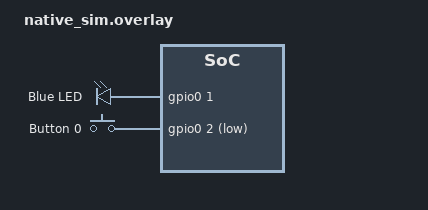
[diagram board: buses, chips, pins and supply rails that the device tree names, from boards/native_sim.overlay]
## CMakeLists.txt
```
# Copyright (c) 2026 Lingao Meng
# SPDX-License-Identifier: Apache-2.0
#
# zbot - An open-source embedded AI Agent for Zephyr RTOS
# Supported boards: nRF7002-DK (nRF5340 + nRF7002 WiFi), native_sim

cmake_minimum_required(VERSION 3.20.0)

find_package(Zephyr REQUIRED HINTS $ENV{ZEPHYR_BASE})

project(zbot VERSION 0.1.0)

target_sources(app PRIVATE
    src/main.c
    src/tools.c
    src/memory.c
    src/config.c
    src/llm_client.c
    src/agent.c
    src/shell_cmd.c
    src/telegram.c
    src/json_util.c
    src/skills/skill.c
)

target_include_directories(app PRIVATE src src/skills src/tools)

set(gen_dir ${ZEPHYR_BINARY_DIR}/include/generated/)

# OpenRouter TLS certificate
generate_inc_file_for_target(
    app
    src/certs/openrouter/cert-3.der
    ${gen_dir}/openrouter/https-cert.der.inc
)

configure_file(
    ${CMAKE_CURRENT_SOURCE_DIR}/src/AGENTS.md.in
    ${gen_dir}/AGENTS.md
    @ONLY
)

# Agent system prompt
generate_inc_file_for_target(
    app
    ${gen_dir}/AGENTS.md
    ${gen_dir}/AGENTS.md.inc
)

add_subdirectory(src/tools)
add_subdirectory(src/skills)
```

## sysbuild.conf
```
#
# Copyright (c) 2024 Nordic Semiconductor ASA
#
# SPDX-License-Identifier: LicenseRef-Nordic-5-Clause
#
# nRF7002 WiFi companion image — only needed for nRF7002DK.
# For other boards (e.g. native_sim) this file is a no-op because
# SB_CONFIG_WIFI_NRF70 is not selected by those board configs.
```

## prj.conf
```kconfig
# =============================================================================
# zbot - Zephyr AI Agent Configuration (all boards)
# =============================================================================

# --- Kernel / Stack ---
CONFIG_MAIN_STACK_SIZE=2048
CONFIG_SYSTEM_WORKQUEUE_STACK_SIZE=16384

CONFIG_PRINTK=y

# --- Shell (for runtime key configuration) ---
CONFIG_SHELL=y
CONFIG_SHELL_BACKEND_SERIAL=y
CONFIG_SHELL_STACK_SIZE=8172
CONFIG_SHELL_CMD_BUFF_SIZE=512
CONFIG_SHELL_HISTORY=y
CONFIG_SHELL_HISTORY_BUFFER=512
CONFIG_SHELL_LOG_BACKEND=n

# --- Networking ---
CONFIG_NETWORKING=y
CONFIG_NET_IPV4=y
CONFIG_NET_TCP=y
CONFIG_NET_SOCKETS=y
CONFIG_NET_SOCKETS_TLS_MAX_CONTEXTS=4
CONFIG_NET_SOCKETS_TLS_MAX_CREDENTIALS=4
CONFIG_NET_SOCKETS_TLS_MAX_CIPHERSUITES=2
CONFIG_DNS_RESOLVER=y

# --- Network buffers ---
CONFIG_NET_PKT_RX_COUNT=8
CONFIG_NET_PKT_TX_COUNT=8
CONFIG_NET_BUF_RX_COUNT=64
CONFIG_NET_BUF_TX_COUNT=64
# NET_BUF_DATA_SIZE depends on NET_BUF_FIXED_DATA_SIZE; enable the guard first.
CONFIG_NET_BUF_FIXED_DATA_SIZE=y
CONFIG_NET_BUF_DATA_SIZE=256

# --- HTTP Client ---
CONFIG_HTTP_CLIENT=y

# --- TLS / mbedTLS ---
CONFIG_MBEDTLS=y
CONFIG_MBEDTLS_BUILTIN=y
CONFIG_NET_SOCKETS_SOCKOPT_TLS=y
CONFIG_TLS_CREDENTIALS=y
# MBEDTLS_HEAP_SIZE lives inside "if MBEDTLS_ENABLE_HEAP"
CONFIG_MBEDTLS_ENABLE_HEAP=y
CONFIG_MBEDTLS_HEAP_SIZE=65536
CONFIG_MBEDTLS_SSL_MAX_CONTENT_LEN=8192
CONFIG_MBEDTLS_SSL_SERVER_NAME_INDICATION=y
CONFIG_MBEDTLS_CIPHERSUITE_TLS_ECDHE_ECDSA_WITH_AES_128_GCM_SHA256=y
# TLS 1.2 ciphersuite — required to pull in the SSL module (mbedtls_ssl_*).
# Without at least one ciphersuite, MBEDTLS_SSL_PROTO_TLS1_2 is never selected
# and all mbedtls_ssl_init/setup/handshake/... symbols are absent at link time.
CONFIG_MBEDTLS_CIPHERSUITE_TLS_ECDHE_RSA_WITH_AES_128_CBC_SHA256=y

CONFIG_SETTINGS=y
CONFIG_SETTINGS_RUNTIME=y
CONFIG_SETTINGS_NVS=y

CONFIG_NVS=y
CONFIG_FLASH=y
CONFIG_FLASH_MAP=y

# --- Logging ---
CONFIG_LOG=y
CONFIG_LOG_DEFAULT_LEVEL=3
CONFIG_LOG_BUFFER_SIZE=4096
CONFIG_LOG_BACKEND_UART=y
CONFIG_PRINTK=y

# --- Reboot support ---
CONFIG_REBOOT=y
```

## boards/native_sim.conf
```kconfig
# =============================================================================
# zbot - Board-specific config for native_sim (Linux host simulation)
# =============================================================================

# --- Native networking (offloaded sockets via host stack) ---
# Use the native Linux network stack via offloaded socket API.
CONFIG_NET_DRIVERS=y
CONFIG_NET_SOCKETS_OFFLOAD=y
CONFIG_NET_NATIVE_OFFLOADED_SOCKETS=y
CONFIG_NET_DHCPV4=y

CONFIG_TEST_RANDOM_GENERATOR=y

# --- POSIX / libc ---
# native_sim provides a full libc; enable POSIX API for compatibility.
CONFIG_REQUIRES_FULL_LIBC=y
CONFIG_POSIX_API=y

# Optional but recommended for native_sim + nsos
CONFIG_ETH_NATIVE_TAP=n
CONFIG_NET_IPV6_DAD=n

CONFIG_MBEDTLS_HASH_ALL_ENABLED=y

# --- GPIO emulation ---
# gpio_emul driver is auto-selected by the DTS compatible "zephyr,gpio-emul".
# Explicitly enable it here as a safety net.
CONFIG_GPIO=y
CONFIG_GPIO_EMUL=y

# Debug
CONFIG_NET_LOG=y
```

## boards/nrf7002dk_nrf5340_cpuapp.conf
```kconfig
# =============================================================================
# zbot - Board-specific config for nRF7002-DK (nRF5340 + nRF7002 WiFi)
# =============================================================================

# --- WiFi (nRF7002) ---
# WIFI_NRF7002 is auto-selected by DT (DT_HAS_NORDIC_NRF7002_QSPI_ENABLED).
# WIFI_NM_WPA_SUPPLICANT is auto-selected by the nrf_wifi driver.
# Do NOT set WIFI_NRF700X or WPA_SUPP — those symbols no longer exist.
CONFIG_WIFI=y
CONFIG_NET_L2_WIFI_MGMT=y
CONFIG_NET_DHCPV4=y
# WiFi connection is handled by 'zbot wifi' commands (shell_cmd.c).
# The built-in wifi shell is intentionally disabled to keep the command
# surface under the single 'zbot' root.

# --- WiFi Credentials (Zephyr built-in, uses SETTINGS+NVS backend) ---
# wifi_credentials stores SSID/pass; NET_REQUEST_WIFI_CONNECT_STORED iterates them.
CONFIG_WIFI_CREDENTIALS=y
CONFIG_WIFI_CREDENTIALS_BACKEND_SETTINGS=y
CONFIG_WIFI_CREDENTIALS_CONNECT_STORED=y
CONFIG_WIFI_CREDENTIALS_SHELL=n

# --- Entropy / RNG ---
# nRF5340 app core has no RNG peripheral in its DTS. The psa-crypto-rng driver
# crashes at PRE_KERNEL_1 (heap not ready). Instead:
#   - TEST_RANDOM_GENERATOR: allows a non-CSPRNG source to satisfy sys_rand_get
#   - TIMER_RANDOM_GENERATOR: provides z_impl_sys_rand_get via system timer
#     (sufficient for TCP ISN and DHCP; not used for TLS key material)
# TLS/mbedTLS crypto RNG is provided by MBEDTLS_PSA_CRYPTO_EXTERNAL_RNG
# which is already set in the board defconfig and uses the software PSA backend.
CONFIG_ENTROPY_GENERATOR=y
CONFIG_TEST_RANDOM_GENERATOR=y
CONFIG_TIMER_RANDOM_GENERATOR=y
```

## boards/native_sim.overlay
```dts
/*
 * Copyright (c) 2026 Lingao Meng
 *
 * SPDX-License-Identifier: Apache-2.0
 *
 * zbot - native_sim GPIO overlay
 *
 * The native_sim base DTS already provides:
 *   gpio0 (zephyr,gpio-emul) — pin 0 → led0
 *
 * This overlay extends gpio0 to 3 pins and adds led1 + sw0 (button0)
 * so that gpio_read / gpio_write tools work the same as on nRF7002-DK.
 */

#include <zephyr/dt-bindings/gpio/gpio.h>

/* Extend the emulated GPIO controller to cover the pins we need */
&gpio0 {
	ngpios = <3>;
};

/ {
	leds {
		compatible = "gpio-leds";

		led1: led_1 {
			gpios = <&gpio0 1 GPIO_ACTIVE_HIGH>;
			label = "Blue LED";
		};
	};

	buttons {
		compatible = "gpio-keys";

		button0: button_0 {
			gpios = <&gpio0 2 (GPIO_PULL_UP | GPIO_ACTIVE_LOW)>;
			label = "Button 0";
		};
	};

	aliases {
		led1 = &led1;
		sw0  = &button0;
	};
};
```

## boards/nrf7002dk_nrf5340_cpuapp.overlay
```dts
/*
 * SPDX-License-Identifier: Apache-2.0
 * nRF7002-DK device tree overlay for ZephyrClaw
 *
 * Ensures storage_partition exists for NVS.
 * The nRF7002-DK (nRF5340) internal flash layout already includes a
 * storage partition in the upstream DTS; this overlay confirms it.
 */

/ {
    chosen {
        zephyr,console = &uart0;
        zephyr,shell-uart = &uart0;
        /*
         * Do NOT add zephyr,entropy here.
         * nRF5340 app core has no RNG peripheral in DTS.
         * The psa-crypto-rng driver calls psa_crypto_init() at PRE_KERNEL_1
         * before the heap is ready, causing a hard fault with no output.
         * Instead, use TEST_RANDOM_GENERATOR + TIMER_RANDOM_GENERATOR in prj.conf
         * to satisfy sys_rand_get(). TLS crypto RNG is handled separately by
         * MBEDTLS_PSA_CRYPTO_EXTERNAL_RNG (set in board defconfig).
         */
    };
};

/*
 * Ensure NVS storage partition is available.
 * On nRF5340 the storage partition is typically defined in:
 *   boards/nordic/nrf7002dk/nrf5340_cpuapp_common.dtsi
 * If it is missing on your SDK version, uncomment and adjust below:
 */

/*
&flash0 {
    partitions {
        compatible = "fixed-partitions";
        #address-cells = <1>;
        #size-cells = <1>;

        boot_partition: partition@0 {
            label = "mcuboot";
            reg = <0x00000000 0x00010000>;
        };

        slot0_partition: partition@10000 {
            label = "image-0";
            reg = <0x00010000 0x00070000>;
        };

        slot1_partition: partition@80000 {
            label = "image-1";
            reg = <0x00080000 0x00070000>;
        };

        storage_partition: partition@f0000 {
            label = "storage";
            reg = <0x000f0000 0x00008000>;
        };
    };
};
*/
```

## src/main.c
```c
/*
 * Copyright (c) 2026 Lingao Meng
 *
 * SPDX-License-Identifier: Apache-2.0
 *
 * zbot - Main Entry Point
 *
 * WiFi (boards with CONFIG_WIFI, e.g. nRF7002-DK):
 *   Use 'zbot wifi connect <ssid> [pass]' to connect and save credentials.
 *   On next boot, config_init() auto-connects using the saved credentials.
 *
 * Without WiFi (e.g. native_sim):
 *   The network stack is provided by the host OS; no WiFi management needed.
 *
 * API key:
 *   'zbot key <key>'  — set and persist to flash
 */

#include <zephyr/kernel.h>
#include <zephyr/logging/log.h>
#include <zephyr/net/net_if.h>
#if defined(CONFIG_WIFI)
#include <zephyr/net/net_event.h>
#include <zephyr/net/wifi_mgmt.h>
#endif

#include "config.h"
#include "memory.h"
#include "llm_client.h"
#include "agent.h"
#include "tools.h"
#include "telegram.h"

LOG_MODULE_REGISTER(zbot_main, LOG_LEVEL_INF);

#if defined(CONFIG_WIFI)
#define WIFI_MGMT_EVENTS (NET_EVENT_WIFI_CONNECT_RESULT | NET_EVENT_WIFI_DISCONNECT_RESULT)

static struct net_mgmt_event_callback g_wifi_cb;
static K_SEM_DEFINE(g_wifi_connected_sem, 0, 1);
static volatile bool g_wifi_connected;

static void wifi_event_handler(struct net_mgmt_event_callback *cb, uint64_t mgmt_event,
			       struct net_if *iface)
{
	if (mgmt_event == NET_EVENT_WIFI_CONNECT_RESULT) {
		const struct wifi_status *status = (const struct wifi_status *)cb->info;

		if (status->status == 0) {
			LOG_INF("WiFi connected!");
			g_wifi_connected = true;
			k_sem_give(&g_wifi_connected_sem);
		} else {
			LOG_WRN("WiFi connect failed (status %d)", status->status);
		}
	} else if (mgmt_event == NET_EVENT_WIFI_DISCONNECT_RESULT) {
		LOG_WRN("WiFi disconnected");
		g_wifi_connected = false;
	}
}
#endif /* CONFIG_WIFI */

static void print_banner(void)
{
	printk("\n");
	printk("╔══════════════════════════════════════════════╗\n");
	printk("║        zbot - Embedded AI Agent              ║\n");
	printk("║   Board: %-36s║\n", CONFIG_BOARD "  |  Zephyr RTOS");
	printk("║   Version: 0.1.0     |  License: Apache-2.0  ║\n");
	printk("╚══════════════════════════════════════════════╝\n");
	printk("\n");
	printk("Quick start:\n");
#if defined(CONFIG_WIFI)
	printk("  1. Connect to WiFi (saves credentials for auto-connect):\n");
	printk("       zbot wifi connect <SSID> <password>\n");
	printk("  2. Set API key (saved to flash):\n");
	printk("       zbot key sk-...\n");
#else
	printk("  1. Set API key (saved to flash):\n");
	printk("       zbot key sk-...\n");
#endif
	printk("  2. [Optional] Change model/endpoint:\n");
	printk("       zbot model gpt-4o-mini\n");
	printk("       zbot host openrouter.ai\n");
	printk("  3. Chat:\n");
	printk("       Hello! What can you do?\n");
	printk("  4. Telegram bot (optional):\n");
	printk("       zbot telegram token <BOT_TOKEN>\n");
	printk("       zbot telegram start\n");
	printk("  5. Other commands:\n");
	printk("       zbot status              -- show config\n");
#if defined(CONFIG_WIFI)
	printk("       zbot wifi status         -- show saved WiFi SSID\n");
#endif
	printk("       zbot history             -- show conversation\n");
	printk("       zbot summary             -- show NVS summary\n");
	printk("       zbot skill list\n");
	printk("       zbot tools\n");
	printk("\n");
}

int main(void)
{
	const char *summary;
	int rc;

	printk("Start\n");

	/* Memory — NVS mount and load persisted summary */
	rc = memory_init();
	if (rc < 0) {
		LOG_WRN("Memory/NVS init warning: %d (continuing without persistence)", rc);
	}

#if defined(CONFIG_WIFI)
	/* Register WiFi event callback */
	net_mgmt_init_event_callback(&g_wifi_cb, wifi_event_handler, WIFI_MGMT_EVENTS);
	net_mgmt_add_event_callback(&g_wifi_cb);
#endif

	/* Config — load API key + (if WiFi board) credentials from NVS; auto-connect */
	config_init();

	/* LLM client — register TLS CA certificate once at boot */
	llm_client_init();

	/* Agent */
	rc = agent_init();
	if (rc < 0) {
		LOG_ERR("Agent init failed: %d", rc);
		return rc;
	}

	/* Telegram */
	if (config_has_tg_token()) {
		rc = telegram_start();
		if (rc < 0) {
			LOG_WRN("Telegram auto-start failed: %d", rc);
		}
	}

	/* Print banner */
	print_banner();

	/* Log persisted summary if available */
	summary = memory_get_summary();
	if (summary != NULL) {
		LOG_DBG("Loaded prior context from NVS: %.80s...", summary);
		printk("  [Prior session context loaded from NVS]\n\n");
	}

	/* Idle — shell handles everything else */
	while (1) {
		k_sleep(K_SECONDS(30));

#if defined(CONFIG_WIFI)
		if (g_wifi_connected) {
			LOG_DBG("Heartbeat — WiFi up");
		}
#endif
	}

	return 0;
}
```

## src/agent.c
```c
/*
 * Copyright (c) 2026 Lingao Meng
 *
 * SPDX-License-Identifier: Apache-2.0
 *
 * zbot - Agent Module Implementation
 *
 * Implements the ReAct (Reason + Act) loop for tool-augmented LLM interaction.
 */

#include <zephyr/kernel.h>
#include <zephyr/logging/log.h>
#include <string.h>
#include <stdio.h>
#include <errno.h>

#include "agent.h"
#include "memory.h"
#include "tools.h"
#include "config.h"
#include "llm_client.h"
#include "json_util.h"

LOG_MODULE_REGISTER(zbot_agent, LOG_LEVEL_INF);

/* System prompt embedded from src/AGENT.md at build time */
const char agent_system_prompt[] = {
#include "AGENTS.md.inc"
	0x00
};

struct tool_turn_ctx {
	size_t pos;

	int call_count;

	const char *content;

	struct {
		const struct llm_tool_call *call;
		char results[LLM_MAX_TOOL_CALLS][TOOLS_RESULT_MAX_LEN];
	} react;
};

struct summary_ctx {
	const char *roles[MEMORY_COMPRESS_COUNT];
	const char *contents[MEMORY_COMPRESS_COUNT];
	const char *prior;
	int count;
};

static int summary_messages_cb(char *buf, size_t buf_len, void *args)
{
	const struct llm_config *cfg = config_get();
	struct summary_ctx *ctx = args;
	const char *prefix;
	size_t pos = 0;
	int n;

	n = snprintf(buf + pos, buf_len - pos,
		     "{\"model\":\"%s\","
		     "\"max_completion_tokens\":%d,"
		     "\"messages\":",
		     cfg->model, cfg->max_tokens);
	if (n < 0 || (size_t)n >= buf_len - pos) {
		return -ENOMEM;
	}

	pos += (size_t)n;


	n = snprintf(buf + pos, buf_len - pos, "[{\"role\":\"system\",\"content\":\"");
	if (n < 0 || (size_t)n >= buf_len - pos) {
		return -ENOMEM;
	}

	pos += n;

	/* 1. System message — escape directly into buf */
	n = json_escape(agent_system_prompt, buf + pos, buf_len - pos);
	if ((size_t)n >= buf_len - pos) {
		return -ENOMEM;
	}

	pos += n;

	n = snprintf(buf + pos, buf_len - pos, "\"},");
	if (n < 0 || (size_t)n >= buf_len - pos) {
		return -ENOMEM;
	}

	pos += n;

	if (ctx->prior != NULL) {
		n = snprintf(buf + pos, buf_len - pos,
			     "{\"role\":\"user\",\"content\":\"[Prior summary] ");
		if (n < 0 || (size_t)n >= buf_len - pos) {
			return -ENOMEM;
		}
		pos += (size_t)n;

		n = json_escape(ctx->prior, buf + pos, buf_len - pos);
		if ((size_t)n >= buf_len - pos) {
			return -ENOMEM;
		}
		pos += (size_t)n;

		n = snprintf(buf + pos, buf_len - pos,
			     "\"},"
			     "{\"role\":\"assistant\",\"content\":\"Understood.\"},");
		if (n < 0 || (size_t)n >= buf_len - pos) {
			return -ENOMEM;
		}
		pos += (size_t)n;
	}

	prefix = (ctx->prior != NULL) ?
		  "Update the prior summary to include the following new turns." :
		  "Summarise the following conversation.";

	n = snprintf(buf + pos, buf_len - pos, "{\"role\":\"user\",\"content\":\"%s %s",
		     prefix, "For future context. Be factual and concise.");
	if (n < 0 || pos + (size_t)n >= buf_len) {
		return -ENOMEM;
	}

	pos += (size_t)n;

	n = snprintf(buf + pos, buf_len - pos, "Keep the result not exceed %d bytes.\\n",
		     MEMORY_SUMMARY_MAX_LEN);
	if (n < 0 || pos + (size_t)n >= buf_len) {
		return -ENOMEM;
	}

	pos += (size_t)n;

	for (int i = 0; i < ctx->count; i++) {
		n = snprintf(buf + pos, buf_len - pos, "%s: ", ctx->roles[i]);
		if (n < 0 || (size_t)n >= buf_len - pos) {
			return -ENOMEM;
		}
		pos += (size_t)n;

		n = json_escape(ctx->contents[i], buf + pos, buf_len - pos);
		if ((size_t)n >= buf_len - pos) {
			return -ENOMEM;
		}
		pos += (size_t)n;

		n = snprintf(buf + pos, buf_len - pos, "\\n");
		if (n < 0 || (size_t)n >= buf_len - pos) {
			return -ENOMEM;
		}
		pos += (size_t)n;
	}

	n = snprintf(buf + pos, buf_len - pos, "\"}]");
	if (n < 0 || pos + (size_t)n >= buf_len) {
		return -ENOMEM;
	}

	pos += (size_t)n;

	return (int)pos;
}

int agent_request_summary(agent_format_fn_t format_fn, char *out_buf, size_t out_len)
{
	struct summary_ctx ctx;
	struct llm_response resp;
	int count, rc;

	if (!format_fn || !out_buf || out_len == 0) {
		return -EINVAL;
	}

	count = format_fn(ctx.roles, ctx.contents, MEMORY_COMPRESS_COUNT);
	if (count < 0) {
		return count;
	}

	if (count == 0) {
		return -ENODATA;
	}

	ctx.count = count;
	ctx.prior = memory_get_summary();

	rc = llm_chat(summary_messages_cb, NULL, &resp, &ctx);
	if (rc == 0 && resp.content[0] != '\0') {
		strncpy(out_buf, resp.content, out_len - 1);
		out_buf[out_len - 1] = '\0';
		LOG_INF("agent_request_summary: %zu chars", strlen(out_buf));
		return 0;
	}

	LOG_WRN("agent_request_summary failed: %d", rc);

	return rc != 0 ? rc : -ENODATA;
}

static int messages_cb(char *buf, size_t buf_len, void *args)
{
	struct tool_turn_ctx *tc = args;
	bool first = false;
	size_t pos;
	int n;

	/*
	 * First tool-call iteration: build the base history and cache the
	 * position so subsequent iterations can skip the rebuild.
	 */
	if (tc->pos == 0) {
		n = memory_build_messages_json(buf, buf_len);
		if (n < 0) {
			return n;
		}

		first = true;
		tc->pos = (size_t)n;
	}

	/*
	 * Strip the closing ']' written by memory_build_messages_json so we
	 * can append more elements, then re-add it at the end.
	 */
	pos = tc->pos;
	if (pos == 0 || buf[pos - 1] != ']') {
		return -EINVAL;
	}
	pos--; /* overwrite the trailing ']' */

	n = snprintf(buf + pos, buf_len - pos, ",{\"role\":\"%s\",\"content\":\"",
		     first ? "user" : "assistant");
	if (n < 0 || (size_t)n >= buf_len - pos) {
		return -ENOMEM;
	}
	pos += (size_t)n;

	if (tc->content) {
		n = json_escape(tc->content, buf + pos, buf_len - pos);
		if ((size_t)n >= buf_len - pos) {
			return -ENOMEM;
		}
		pos += (size_t)n;
	}

	if (first) {
		n = snprintf(buf + pos, buf_len - pos, "\"}]");
		if (n < 0 || (size_t)n >= buf_len - pos) {
			return -ENOMEM;
		}

		pos += (size_t)n;
		tc->pos = pos;

		return (int)pos;
	}

	n = snprintf(buf + pos, buf_len - pos, "\",\"tool_calls\":[");
	if (n < 0 || (size_t)n >= buf_len - pos) {
		return -ENOMEM;
	}
	pos += (size_t)n;

	for (int i = 0; i < tc->call_count; i++) {
		const struct llm_tool_call *call = &tc->react.call[i];

		n = snprintf(buf + pos, buf_len - pos,
			     "%s{\"id\":\"%s\","
			     "\"type\":\"function\","
			     "\"function\":{\"name\":\"%s\",\"arguments\":\"",
			     i > 0 ? "," : "", call->id, call->name);
		if (n < 0 || (size_t)n >= buf_len - pos) {
			return -ENOMEM;
		}
		pos += (size_t)n;

		n = json_escape(call->arguments, buf + pos, buf_len - pos);
		if ((size_t)n >= buf_len - pos) {
			return -ENOMEM;
		}
		pos += (size_t)n;

		n = snprintf(buf + pos, buf_len - pos, "\"}}");
		if (n < 0 || (size_t)n >= buf_len - pos) {
			return -ENOMEM;
		}
		pos += (size_t)n;
	}

	n = snprintf(buf + pos, buf_len - pos, "]}");
	if (n < 0 || (size_t)n >= buf_len - pos) {
		return -ENOMEM;
	}
	pos += (size_t)n;

	/*
	 * Append one tool result message per tool call:
	 *   {"role":"tool","tool_call_id":"...","content":"..."}
	 */
	for (int i = 0; i < tc->call_count; i++) {
		n = snprintf(buf + pos, buf_len - pos,
			     ",{\"role\":\"tool\","
			     "\"tool_call_id\":\"%s\","
			     "\"content\":\"",
			     tc->react.call[i].id);
		if (n < 0 || (size_t)n >= buf_len - pos) {
			return -ENOMEM;
		}
		pos += (size_t)n;

		n = json_escape(tc->react.results[i], buf + pos, buf_len - pos);
		if ((size_t)n >= buf_len - pos) {
			return -ENOMEM;
		}
		pos += (size_t)n;

		n = snprintf(buf + pos, buf_len - pos, "\"}");
		if (n < 0 || (size_t)n >= buf_len - pos) {
			return -ENOMEM;
		}
		pos += (size_t)n;
	}

	/* Re-add closing ']' */
	n = snprintf(buf + pos, buf_len - pos, "]");
	if (n < 0 || (size_t)n >= buf_len - pos) {
		return -ENOMEM;
	}
	pos += (size_t)n;

	tc->pos = pos;

	return (int)pos;
}

static int tools_cb(char *buf, size_t buf_len, void *args)
{
	ARG_UNUSED(args);

	return tools_build_json(buf, buf_len);
}

/*
 * Dispatch an LLM tool_call to the registered handler.
 * All tools (tool_exec, read_skill, …) are in the linked list —
 * no hard-coded names here.
 */
static int agent_dispatch_tool(const char *name, const char *args_json,
				char *result, size_t res_len)
{
	return tools_execute(name, args_json, result, res_len);
}

static int react_loop(const char *user_input, agent_response_cb cb, void *user_data)
{
	struct tool_turn_ctx tc = {
		.content = user_input,
	};
	struct llm_response resp;
	int iterations = 0;
	int rc;

	while (iterations < AGENT_MAX_REACT_ITERATIONS) {
		iterations++;

		LOG_DBG("ReAct iteration %d / %d", iterations, AGENT_MAX_REACT_ITERATIONS);

		rc = llm_chat(messages_cb, tools_cb, &resp, &tc);
		if (rc < 0) {
			LOG_ERR("LLM call failed: %d", rc);
			if (cb) {
				cb(rc, "[Error: LLM request failed]", false, user_data);
			}
			return rc;
		}

		/* --- Tool call branch --- */
		if (resp.finish_reason == LLM_FINISH_TOOL_CALL && resp.tool_call_count > 0) {
			/* Deliver intermediate content if the model produced any */
			if (resp.content[0] != '\0' && cb) {
				cb(0, resp.content, true, user_data);
			}

			tc.call_count = resp.tool_call_count;

			/* Execute each tool call via unified dispatch */
			for (int i = 0; i < resp.tool_call_count; i++) {
				const char *tname = resp.tool_calls[i].name;
				const char *targs = resp.tool_calls[i].arguments;

				rc = agent_dispatch_tool(tname, targs,
							 tc.react.results[i],
							 sizeof(tc.react.results[i]));
				if (rc < 0) {
					LOG_WRN("tool_call[%d] %s failed: %d", i, tname, rc);
				}
			}

			tc.react.call = resp.tool_calls;
			tc.content = resp.content;
			continue;
		}

		/* --- Stop / final response --- */
		if (resp.content[0] != '\0') {
			/* Add user turn to history */
			rc = memory_add_turn("user", user_input);
			if (rc < 0) {
				LOG_ERR("Failed to add user turn: %d", rc);
				return rc;
			}

			/* Add assistant response to history */
			rc = memory_add_turn("assistant", resp.content);
			if (rc < 0) {
				LOG_ERR("Failed to add assistant turn: %d", rc);
				return rc;
			}

			if (cb) {
				cb(0, resp.content, false, user_data);
			}

			return 0;
		}

		/* Empty response — stop */
		LOG_WRN("Empty LLM response");

		if (cb) {
			cb(-ENODATA, "[No response from model]", false, user_data);
		}

		return -ENODATA;
	}

	/* Max iterations reached */
	LOG_WRN("Max ReAct iterations reached");

	if (cb) {
		cb(-ELOOP, "[Max tool iterations reached]", false, user_data);
	}

	return -ELOOP;
}

int agent_init(void)
{
	LOG_INF("zbot agent initialised (max ReAct iterations: %d)", AGENT_MAX_REACT_ITERATIONS);

	return 0;
}

static void agent_work_handler(struct k_work *work);

static struct agent_work_item {
	struct k_work work;
	char input[AGENT_INPUT_MAX_LEN];
	agent_response_cb cb;
	void *user_data;
} g_work_item = {
	.work = Z_WORK_INITIALIZER(agent_work_handler),
};

bool agent_is_busy(void)
{
	return k_work_busy_get(&g_work_item.work) & (K_WORK_RUNNING | K_WORK_QUEUED);
}

static void agent_work_handler(struct k_work *work)
{
	struct agent_work_item *item = CONTAINER_OF(work, struct agent_work_item, work);

	react_loop(item->input, item->cb, item->user_data);
}

int agent_submit_input(const char *input, agent_response_cb cb, void *user_data)
{
	if (!input || strlen(input) == 0) {
		return -EINVAL;
	}

	if (agent_is_busy()) {
		LOG_WRN("Agent is busy");
		return -EBUSY;
	}

	if (strlen(input) >= AGENT_INPUT_MAX_LEN) {
		LOG_ERR("Input too long (%zu > %d)", strlen(input), AGENT_INPUT_MAX_LEN - 1);
		return -EINVAL;
	}

	strncpy(g_work_item.input, input, AGENT_INPUT_MAX_LEN - 1);
	g_work_item.input[AGENT_INPUT_MAX_LEN - 1] = '\0';

	g_work_item.cb = cb;
	g_work_item.user_data = user_data;

	k_work_submit(&g_work_item.work);

	return 0;
}
```

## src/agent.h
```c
/*
 * Copyright (c) 2026 Lingao Meng
 *
 * SPDX-License-Identifier: Apache-2.0
 *
 * zbot - Agent Module
 *
 * The Agent is the core reasoning loop (ReAct pattern):
 *
 *   1. Receive user input
 *   2. Add to memory history
 *   3. Build messages JSON (system + summary + history)
 *   4. Call LLM with tools schema
 *   5. If finish_reason == tool_call:
 *        a. Execute the requested tool
 *        b. Add tool result to history as "tool" role message
 *        c. Go to step 3 (loop until stop or max iterations)
 *   6. Return final assistant response
 *   7. Request summary update from LLM and persist to NVS
 *
 * The agent runs in its own Zephyr thread. User input is pushed via
 * agent_submit_input(). The response is delivered via a callback.
 */

#ifndef ZBOT_AGENT_H
#define ZBOT_AGENT_H

#include <stddef.h>
#include <stdio.h>
#include <errno.h>

#ifdef __cplusplus
extern "C" {
#endif

/* Maximum ReAct loop iterations before forcing a stop */
#define AGENT_MAX_REACT_ITERATIONS 10

#define AGENT_INPUT_MAX_LEN  512
#define AGENT_OUTPUT_MAX_LEN 1024

/* clang-format off */
/* System prompt loaded from src/AGENT.md at build time */
extern const char agent_system_prompt[];
/* clang-format on */

/**
 * @brief Response callback — called from the agent thread.
 *
 * Called once for each intermediate assistant message (during tool-call
 * iterations where the model produces visible content) and once for the
 * final response.
 *
 * @param err             0 on success, negative on error.
 * @param content         NUL-terminated response text (never NULL).
 * @param is_intermediate true if this is a mid-loop assistant message,
 *                        false for the final response.
 * @param user_data       Opaque pointer passed to agent_submit_input().
 */
typedef void (*agent_response_cb)(int err, const char *content,
				  bool is_intermediate, void *user_data);

/**
 * @brief Initialise the agent (call after memory, tools, skills init).
 * @return 0 on success.
 */
int agent_init(void);

/**
 * @brief Submit a user message for processing.
 *
 * Thread-safe. The agent processes the message asynchronously and invokes
 * @p cb for each response fragment.
 *
 * @param input      User input string.
 * @param cb         Response callback; may be NULL.
 * @param user_data  Opaque pointer forwarded to every @p cb invocation.
 * @return 0 on success, -EBUSY if agent is already processing, -EINVAL on bad input.
 */
int agent_submit_input(const char *input, agent_response_cb cb, void *user_data);

/**
 * @brief Check if the agent is currently processing a request.
 */
bool agent_is_busy(void);

#ifdef __cplusplus
}
#endif

/**
 * @brief Callback provided by the caller to format (collect) the turns to
 *        be summarised.
 *
 * The callback fills @p roles_out and @p contents_out with pointers to at
 * most @p max_count turns (oldest first) and returns the actual count
 * collected.  Returning 0 means nothing to summarise (-ENODATA is returned
 * to the original caller).  A negative return is propagated as-is.
 */
typedef int (*agent_format_fn_t)(const char **roles_out, const char **contents_out, int max_count);

/**
 * @brief Request a summary of the conversation context.
 *
 * Calls @p format_fn to collect the turns, then sends a standalone LLM
 * request and writes the result to @p out_buf.
 *
 * @param format_fn  Callback that fills roles/contents arrays; returns count.
 * @param out_buf    Output buffer for the summary text.
 * @param out_len    Output buffer size.
 * @return 0 on success, -ENODATA if format_fn returned 0, negative on error.
 */
int agent_request_summary(agent_format_fn_t format_fn, char *out_buf, size_t out_len);

#endif /* ZBOT_AGENT_H */
```

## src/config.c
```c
/*
 * Copyright (c) 2026 Lingao Meng
 *
 * SPDX-License-Identifier: Apache-2.0
 *
 * zbot - Config Module Implementation
 */

#include <zephyr/kernel.h>
#include <zephyr/logging/log.h>
#include <zephyr/settings/settings.h>
#include <zephyr/net/net_if.h>
#if defined(CONFIG_WIFI)
#include <zephyr/net/wifi_mgmt.h>
#include <zephyr/net/wifi_credentials.h>
#endif
#include <string.h>
#include <errno.h>

#include "config.h"

LOG_MODULE_REGISTER(zbot_config, LOG_LEVEL_INF);

#define DEFAULT_ENDPOINT_HOST "openrouter.ai"
#define DEFAULT_ENDPOINT_PATH "/api/v1/chat/completions"
#define DEFAULT_MODEL         "minimax/minimax-m2.5"
#define DEFAULT_MAX_TOKENS    512
#define DEFAULT_TEMP_X100     70

static struct llm_config g_cfg = {
	.use_tls = true,
	.port = 443,
	.max_tokens = DEFAULT_MAX_TOKENS,
	.temperature_x100 = DEFAULT_TEMP_X100,
	.endpoint_host = DEFAULT_ENDPOINT_HOST,
	.endpoint_path = DEFAULT_ENDPOINT_PATH,
	.model = DEFAULT_MODEL,
};

/* ------------------------------------------------------------------ */
/* Settings handler — loads all persisted fields at boot              */
/* ------------------------------------------------------------------ */

static int zc_config_set(const char *name, size_t len, settings_read_cb read_cb, void *cb_arg)
{
	size_t read_len;
	int rc;

	if (strcmp(name, "apikey") == 0) {
		read_len = MIN(len, sizeof(g_cfg.api_key) - 1);
		rc = read_cb(cb_arg, g_cfg.api_key, read_len);
		if (rc >= 0) {
			g_cfg.api_key[read_len] = '\0';
		}
		return rc < 0 ? rc : 0;
	}

	if (strcmp(name, "host") == 0) {
		read_len = MIN(len, sizeof(g_cfg.endpoint_host) - 1);
		rc = read_cb(cb_arg, g_cfg.endpoint_host, read_len);
		if (rc >= 0) {
			g_cfg.endpoint_host[read_len] = '\0';
		}
		return rc < 0 ? rc : 0;
	}

	if (strcmp(name, "path") == 0) {
		read_len = MIN(len, sizeof(g_cfg.endpoint_path) - 1);
		rc = read_cb(cb_arg, g_cfg.endpoint_path, read_len);
		if (rc >= 0) {
			g_cfg.endpoint_path[read_len] = '\0';
		}
		return rc < 0 ? rc : 0;
	}

	if (strcmp(name, "model") == 0) {
		read_len = MIN(len, sizeof(g_cfg.model) - 1);
		rc = read_cb(cb_arg, g_cfg.model, read_len);
		if (rc >= 0) {
			g_cfg.model[read_len] = '\0';
		}
		return rc < 0 ? rc : 0;
	}

	if (strcmp(name, "provider_id") == 0) {
		read_len = MIN(len, sizeof(g_cfg.provider_id) - 1);
		rc = read_cb(cb_arg, g_cfg.provider_id, read_len);
		if (rc >= 0) {
			g_cfg.provider_id[read_len] = '\0';
		}
		return rc < 0 ? rc : 0;
	}

	if (strcmp(name, "use_tls") == 0 && len == sizeof(uint8_t)) {
		uint8_t v;

		rc = read_cb(cb_arg, &v, sizeof(v));
		if (rc >= 0) {
			g_cfg.use_tls = (bool)v;
		}
		return rc < 0 ? rc : 0;
	}

	if (strcmp(name, "port") == 0 && len == sizeof(uint16_t)) {
		rc = read_cb(cb_arg, &g_cfg.port, sizeof(g_cfg.port));
		return rc < 0 ? rc : 0;
	}

	if (strcmp(name, "tg_token") == 0) {
		read_len = MIN(len, sizeof(g_cfg.tg_token) - 1);
		rc = read_cb(cb_arg, g_cfg.tg_token, read_len);
		if (rc >= 0) {
			g_cfg.tg_token[read_len] = '\0';
		}
		return rc < 0 ? rc : 0;
	}

	return -ENOENT;
}

SETTINGS_STATIC_HANDLER_DEFINE(zc_config, "zbot", NULL, zc_config_set, NULL, NULL);

/* ------------------------------------------------------------------ */
/* Init                                                               */
/* ------------------------------------------------------------------ */

#if defined(CONFIG_WIFI)
static void print_ssid_cb(void *cb_arg, const char *ssid, size_t ssid_len)
{
	ARG_UNUSED(cb_arg);
	printk("[config] WiFi credentials found (%.*s) — auto-connecting...\n",
	       (int)ssid_len, ssid);
}
#endif

void config_init(void)
{
	/* settings_subsys_init() and settings_load_subtree("zbot") are called
	 * by memory_init() before config_init(). Our handler above will have
	 * already overwritten the defaults with any persisted values. */

	if (g_cfg.api_key[0] != '\0') {
		printk("[config] API key loaded from flash.\n");
	} else {
		printk("[config] No API key stored. Use: zbot key <key>\n");
	}

	LOG_INF("Config init. Endpoint: %s%s model: %s", g_cfg.endpoint_host,
		g_cfg.endpoint_path, g_cfg.model);

#if defined(CONFIG_WIFI)
	/* Auto-connect WiFi if credentials were saved in wifi_credentials */
	if (!wifi_credentials_is_empty()) {
		wifi_credentials_for_each_ssid(print_ssid_cb, NULL);
		config_wifi_auto_connect();
	}
#endif
}

/* ------------------------------------------------------------------ */
/* Getters / setters                                                  */
/* ------------------------------------------------------------------ */

const struct llm_config *config_get(void)
{
	return &g_cfg;
}

int config_set_api_key(const char *key)
{
	int rc;

	if (!key || strlen(key) >= CONFIG_API_KEY_MAX_LEN) {
		return -EINVAL;
	}

	strncpy(g_cfg.api_key, key, sizeof(g_cfg.api_key) - 1);
	g_cfg.api_key[sizeof(g_cfg.api_key) - 1] = '\0';

	rc = settings_save_one("zbot/apikey", g_cfg.api_key, strlen(g_cfg.api_key) + 1);
	if (rc < 0) {
		LOG_ERR("Failed to persist api_key: %d", rc);
	}

	return rc;
}

int config_set_endpoint_host(const char *host)
{
	int rc;

	if (!host || strlen(host) >= CONFIG_ENDPOINT_MAX_LEN) {
		return -EINVAL;
	}

	strncpy(g_cfg.endpoint_host, host, sizeof(g_cfg.endpoint_host) - 1);
	g_cfg.endpoint_host[sizeof(g_cfg.endpoint_host) - 1] = '\0';

	rc = settings_save_one("zbot/host", g_cfg.endpoint_host,
			       strlen(g_cfg.endpoint_host) + 1);
	if (rc < 0) {
		LOG_ERR("Failed to persist host: %d", rc);
	}

	return rc;
}

int config_set_endpoint_path(const char *path)
{
	int rc;

	if (!path || strlen(path) >= CONFIG_ENDPOINT_MAX_LEN) {
		return -EINVAL;
	}

	strncpy(g_cfg.endpoint_path, path, sizeof(g_cfg.endpoint_path) - 1);
	g_cfg.endpoint_path[sizeof(g_cfg.endpoint_path) - 1] = '\0';

	rc = settings_save_one("zbot/path", g_cfg.endpoint_path,
			       strlen(g_cfg.endpoint_path) + 1);
	if (rc < 0) {
		LOG_ERR("Failed to persist path: %d", rc);
	}

	return rc;
}

int config_set_model(const char *model)
{
	int rc;

	if (!model || strlen(model) >= CONFIG_MODEL_MAX_LEN) {
		return -EINVAL;
	}

	strncpy(g_cfg.model, model, sizeof(g_cfg.model) - 1);
	g_cfg.model[sizeof(g_cfg.model) - 1] = '\0';

	rc = settings_save_one("zbot/model", g_cfg.model, strlen(g_cfg.model) + 1);
	if (rc < 0) {
		LOG_ERR("Failed to persist model: %d", rc);
	}

	return rc;
}

int config_set_provider_id(const char *provider_id)
{
	int rc;

	if (!provider_id || strlen(provider_id) >= CONFIG_PROVIDER_ID_MAX_LEN) {
		return -EINVAL;
	}

	strncpy(g_cfg.provider_id, provider_id, sizeof(g_cfg.provider_id) - 1);
	g_cfg.provider_id[sizeof(g_cfg.provider_id) - 1] = '\0';

	rc = settings_save_one("zbot/provider_id", g_cfg.provider_id,
			       strlen(g_cfg.provider_id) + 1);
	if (rc < 0) {
		LOG_ERR("Failed to persist provider_id: %d", rc);
	}

	return rc;
}

int config_set_tls(bool use_tls, uint16_t port)
{
	uint8_t v = (uint8_t)use_tls;
	int rc;

	g_cfg.use_tls = use_tls;
	g_cfg.port = port;

	rc = settings_save_one("zbot/use_tls", &v, sizeof(v));
	if (rc < 0) {
		LOG_ERR("Failed to persist use_tls: %d", rc);
		return rc;
	}

	rc = settings_save_one("zbot/port", &g_cfg.port, sizeof(g_cfg.port));
	if (rc < 0) {
		LOG_ERR("Failed to persist port: %d", rc);
	}

	return rc;
}

bool config_has_api_key(void)
{
	return g_cfg.api_key[0] != '\0';
}

int config_delete_api_key(void)
{
	memset(g_cfg.api_key, 0, sizeof(g_cfg.api_key));

	return settings_delete("zbot/apikey");
}

int config_set_tg_token(const char *token)
{
	int rc;

	if (!token || strlen(token) >= CONFIG_TG_TOKEN_MAX_LEN) {
		return -EINVAL;
	}

	strncpy(g_cfg.tg_token, token, sizeof(g_cfg.tg_token) - 1);
	g_cfg.tg_token[sizeof(g_cfg.tg_token) - 1] = '\0';

	rc = settings_save_one("zbot/tg_token", g_cfg.tg_token, strlen(g_cfg.tg_token) + 1);
	if (rc < 0) {
		LOG_ERR("Failed to persist tg_token: %d", rc);
	}

	return rc;
}

bool config_has_tg_token(void)
{
	return g_cfg.tg_token[0] != '\0';
}

int config_delete_tg_token(void)
{
	memset(g_cfg.tg_token, 0, sizeof(g_cfg.tg_token));

	return settings_delete("zbot/tg_token");
}

int config_reset(void)
{
	static const struct llm_config defaults = {
		.use_tls = true,
		.port = 443,
		.max_tokens = DEFAULT_MAX_TOKENS,
		.temperature_x100 = DEFAULT_TEMP_X100,
		.endpoint_host = DEFAULT_ENDPOINT_HOST,
		.endpoint_path = DEFAULT_ENDPOINT_PATH,
		.model = DEFAULT_MODEL,
	};
	static const char * const zbot_keys[] = {
		"zbot/apikey",
		"zbot/host",
		"zbot/path",
		"zbot/model",
		"zbot/provider_id",
		"zbot/use_tls",
		"zbot/port",
		"zbot/tg_token",
	};
	int rc;

	g_cfg = defaults;

	for (int i = 0; i < ARRAY_SIZE(zbot_keys); i++) {
		rc = settings_delete(zbot_keys[i]);
		if (rc < 0) {
			return rc;
		}
	}

	return 0;
}

void config_print_status(void)
{
	printk("=== zbot Config ===\n");
	printk("  Endpoint : %s:%u%s\n", g_cfg.endpoint_host, g_cfg.port, g_cfg.endpoint_path);
	printk("  Model    : %s\n", g_cfg.model);
	printk("  Provider : %s\n", g_cfg.provider_id[0] ? g_cfg.provider_id : "(not set)");
	printk("  TLS      : %s\n", g_cfg.use_tls ? "yes" : "no");
	printk("  API Key  : %s\n", g_cfg.api_key[0] ? "*** (set)" : "(not set)");
	printk("  TG Token : %s\n", g_cfg.tg_token[0] ? "*** (set)" : "(not set)");
	printk("  Max Tok  : %d\n", g_cfg.max_tokens);
	printk("  Temp     : %d.%02d\n", g_cfg.temperature_x100 / 100,
	       g_cfg.temperature_x100 % 100);
#if defined(CONFIG_WIFI)
	printk("  WiFi cred: %s\n", wifi_credentials_is_empty() ? "(not saved)" : "(saved)");
#endif
}

/* ------------------------------------------------------------------ */
/* WiFi helpers (backed by Zephyr wifi_credentials subsystem)         */
/* Only compiled when CONFIG_WIFI is enabled (e.g. nRF7002-DK).       */
/* ------------------------------------------------------------------ */
#if defined(CONFIG_WIFI)

struct wifi_delete_ctx {
	const char *new_ssid;
	size_t new_ssid_len;
};

static void delete_different_ssid_cb(void *cb_arg, const char *ssid, size_t ssid_len)
{
	struct wifi_delete_ctx *ctx = cb_arg;

	if (ssid_len != ctx->new_ssid_len ||
	    memcmp(ssid, ctx->new_ssid, ssid_len) != 0) {
		LOG_INF("Deleting old WiFi credentials for different SSID");
		wifi_credentials_delete_by_ssid(ssid, ssid_len);
	}
}

int config_wifi_connect(const char *ssid, const char *pass)
{
	struct net_if *iface = net_if_get_wifi_sta();
	struct wifi_connect_req_params params = {0};
	enum wifi_security_type sec;
	int rc;

	if (!ssid || ssid[0] == '\0') {
		return -EINVAL;
	}

	if (!iface) {
		LOG_ERR("No default network interface");
		return -ENODEV;
	}

	sec = (pass && pass[0] != '\0') ? WIFI_SECURITY_TYPE_PSK : WIFI_SECURITY_TYPE_NONE;

	/* If stored credentials exist for a different SSID, delete them first */
	if (!wifi_credentials_is_empty()) {
		struct wifi_delete_ctx ctx = {
			.new_ssid = ssid,
			.new_ssid_len = strlen(ssid),
		};
		wifi_credentials_for_each_ssid(delete_different_ssid_cb, &ctx);
	}

	/* Persist via wifi_credentials subsystem (settings+NVS backend) */
	rc = wifi_credentials_set_personal(ssid, strlen(ssid), sec, NULL, 0, pass ? pass : "",
					   pass ? strlen(pass) : 0, 0, 0, 0);
	if (rc < 0) {
		LOG_ERR("Failed to save WiFi credentials: %d", rc);
		return rc;
	}

	/* Issue connect request immediately */
	params.ssid = (const uint8_t *)ssid;
	params.ssid_length = strlen(ssid);
	params.security = sec;
	if (sec == WIFI_SECURITY_TYPE_PSK) {
		params.psk = (const uint8_t *)pass;
		params.psk_length = strlen(pass);
	}
	params.channel = WIFI_CHANNEL_ANY;
	params.band = WIFI_FREQ_BAND_UNKNOWN;
	params.mfp = WIFI_MFP_OPTIONAL;

	return net_mgmt(NET_REQUEST_WIFI_CONNECT, iface, &params, sizeof(params));
}

int config_wifi_disconnect(void)
{
	struct net_if *iface = net_if_get_wifi_sta();

	if (!iface) {
		return -ENODEV;
	}

	return net_mgmt(NET_REQUEST_WIFI_DISCONNECT, iface, NULL, 0);
}

static void wifi_connect_handler(struct k_work *work)
{
	struct net_if *iface = net_if_get_wifi_sta();
	int rc;

	if (!iface) {
		return;
	}

	rc = net_mgmt(NET_REQUEST_WIFI_CONNECT_STORED, iface, NULL, 0);
	if (rc) {
		LOG_ERR("WIFI Request Connection failed (err %d)", rc);
	}
}

static K_WORK_DELAYABLE_DEFINE(wifi_connect, wifi_connect_handler);

void config_wifi_auto_connect(void)
{
	k_work_reschedule(&wifi_connect, K_SECONDS(1));
}

#endif /* CONFIG_WIFI */
```

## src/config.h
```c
/*
 * Copyright (c) 2026 Lingao Meng
 *
 * SPDX-License-Identifier: Apache-2.0
 *
 * zbot - Config Module
 *
 * Runtime LLM configuration persisted to NVS via Zephyr settings subsystem.
 * Every config_set_*() call writes through to flash immediately.
 * Settings are loaded back at boot inside config_init().
 *
 * Persistent keys (subtree "zbot"):
 *   "zbot/apikey"      : API key
 *   "zbot/host"        : LLM endpoint host
 *   "zbot/path"        : LLM endpoint path
 *   "zbot/model"       : model name
 *   "zbot/provider_id" : X-Model-Provider-Id header value
 *   "zbot/use_tls"     : TLS enabled flag (uint8_t)
 *   "zbot/port"        : TCP port (uint16_t)
 *   "zbot/tg_token"    : Telegram Bot API token
 *
 * Note: "zbot/summary" is managed by memory.c under the same subtree.
 * WiFi credentials are stored by the Zephyr wifi_credentials subsystem
 * (only available when CONFIG_WIFI is enabled).
 */

#ifndef ZBOT_CONFIG_H
#define ZBOT_CONFIG_H

#include <stdbool.h>
#include <stdint.h>
#include <stddef.h>

#ifdef __cplusplus
extern "C" {
#endif

/* Field size limits */
#define CONFIG_API_KEY_MAX_LEN     256
#define CONFIG_ENDPOINT_MAX_LEN    128
#define CONFIG_MODEL_MAX_LEN       64
#define CONFIG_PROVIDER_ID_MAX_LEN 64
#define CONFIG_TG_TOKEN_MAX_LEN    128

/**
 * @brief Runtime LLM configuration — all fields persisted to NVS.
 */
struct llm_config {
	char api_key[CONFIG_API_KEY_MAX_LEN];
	char endpoint_host[CONFIG_ENDPOINT_MAX_LEN];
	char endpoint_path[CONFIG_ENDPOINT_MAX_LEN];
	char model[CONFIG_MODEL_MAX_LEN];
	char provider_id[CONFIG_PROVIDER_ID_MAX_LEN];
	char tg_token[CONFIG_TG_TOKEN_MAX_LEN];
	bool use_tls;
	uint16_t port;
	int max_tokens;
	int temperature_x100; /* stored as int, e.g. 70 = 0.7 */
};

/**
 * @brief Initialise config with defaults, then reload all persisted values
 *        from NVS.  Must be called after settings_subsys_init().
 */
void config_init(void);

/** @brief Get read-only pointer to the current runtime config. */
const struct llm_config *config_get(void);

/** @brief Set API key and persist to flash. */
int config_set_api_key(const char *key);

/** @brief Set LLM endpoint host and persist to flash. */
int config_set_endpoint_host(const char *host);

/** @brief Set API path and persist to flash. */
int config_set_endpoint_path(const char *path);

/** @brief Set model name and persist to flash. */
int config_set_model(const char *model);

/** @brief Set X-Model-Provider-Id header value and persist to flash. */
int config_set_provider_id(const char *provider_id);

/** @brief Set TLS mode and port and persist to flash. */
int config_set_tls(bool use_tls, uint16_t port);

/** @brief Set Telegram Bot token and persist to flash. */
int config_set_tg_token(const char *token);

/** @brief Check whether a Telegram token is set in RAM. */
bool config_has_tg_token(void);

/** @brief Delete the Telegram token from RAM and flash. */
int config_delete_tg_token(void);

/** @brief Check whether an API key is set in RAM. */
bool config_has_api_key(void);

/** @brief Delete the API key from RAM and flash. */
int config_delete_api_key(void);

/** @brief Reset all config to defaults and delete all persisted keys from flash. */
int config_reset(void);

#if defined(CONFIG_WIFI)
/**
 * @brief Save WiFi credentials via wifi_credentials subsystem and connect.
 *
 * Only available when CONFIG_WIFI is enabled (e.g. nRF7002-DK).
 *
 * @param ssid  Network SSID.
 * @param pass  Passphrase, or NULL/empty for open networks.
 * @return 0 on success, negative errno on failure.
 */
int config_wifi_connect(const char *ssid, const char *pass);

/** @brief Disconnect from current WiFi network. */
int config_wifi_disconnect(void);

/**
 * @brief Auto-connect using all credentials stored in wifi_credentials.
 *
 * Issues NET_REQUEST_WIFI_CONNECT_STORED on the default interface.
 * Called automatically on boot by config_init() if credentials exist.
 */
void config_wifi_auto_connect(void);
#endif /* CONFIG_WIFI */

/** @brief Print current config to serial (redacts API key). */
void config_print_status(void);

#ifdef __cplusplus
}
#endif

#endif /* ZBOT_CONFIG_H */
```

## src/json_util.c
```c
/*
 * Copyright (c) 2026 Lingao Meng
 *
 * SPDX-License-Identifier: Apache-2.0
 *
 * zbot - JSON utility implementation
 */

#include <string.h>
#include <stdio.h>
#include <stdlib.h>
#include <inttypes.h>
#include <errno.h>

#include "json_util.h"

int json_get_str(const char *json, const char *key, char *out, size_t out_len)
{
	char search[80];
	const char *pos;
	size_t i = 0;

	if (!json || !key || !out) {
		return -EINVAL;
	}

	snprintf(search, sizeof(search), "\"%s\"", key);
	pos = strstr(json, search);
	if (!pos) {
		return -ENOENT;
	}

	pos += strlen(search);
	while (*pos == ' ' || *pos == ':' || *pos == '\t') {
		pos++;
	}
	if (*pos == 'n') { /* null */
		out[0] = '\0';
		return 0;
	}
	if (*pos != '"') {
		return -ENOENT;
	}
	pos++;

	while (*pos != '\0' && i + 1 < out_len) {
		if (*pos == '\\') {
			pos++;
			switch (*pos) {
			case 'n':  out[i++] = '\n'; pos++; break;
			case 't':  out[i++] = '\t'; pos++; break;
			case '"':  out[i++] = '"';  pos++; break;
			case '\\': out[i++] = '\\'; pos++; break;
			case 'u': {
				/* Decode \uXXXX, with UTF-16 surrogate pair support */
				pos++;
				if (pos[0] && pos[1] && pos[2] && pos[3]) {
					char hex[5] = {pos[0], pos[1], pos[2], pos[3], '\0'};
					uint32_t cp = (uint32_t)strtoul(hex, NULL, 16);

					pos += 4;

					/* High surrogate \uD800–\uDBFF followed by \uDC00–\uDFFF */
					if (cp >= 0xD800 && cp <= 0xDBFF &&
					    pos[0] == '\\' && pos[1] == 'u' &&
					    pos[2] && pos[3] && pos[4] && pos[5]) {
						char hex2[5] = {pos[2], pos[3], pos[4], pos[5], '\0'};
						uint32_t lo = (uint32_t)strtoul(hex2, NULL, 16);

						if (lo >= 0xDC00 && lo <= 0xDFFF) {
							cp = 0x10000u +
							     ((cp - 0xD800u) << 10) +
							     (lo - 0xDC00u);
							pos += 6;
						}
					}

					/* Encode as UTF-8 */
					if (cp < 0x80u) {
						if (i + 1 < out_len) {
							out[i++] = (char)cp;
						}
					} else if (cp < 0x800u) {
						if (i + 2 < out_len) {
							out[i++] = (char)(0xC0u | (cp >> 6));
							out[i++] = (char)(0x80u | (cp & 0x3Fu));
						}
					} else if (cp < 0x10000u) {
						if (i + 3 < out_len) {
							out[i++] = (char)(0xE0u | (cp >> 12));
							out[i++] = (char)(0x80u | ((cp >> 6) & 0x3Fu));
							out[i++] = (char)(0x80u | (cp & 0x3Fu));
						}
					} else {
						/* U+10000–U+10FFFF: emoji range, 4-byte UTF-8 */
						if (i + 4 < out_len) {
							out[i++] = (char)(0xF0u | (cp >> 18));
							out[i++] = (char)(0x80u | ((cp >> 12) & 0x3Fu));
							out[i++] = (char)(0x80u | ((cp >> 6) & 0x3Fu));
							out[i++] = (char)(0x80u | (cp & 0x3Fu));
						}
					}
				}
				break;
			}
			default: out[i++] = *pos++; break;
			}
		} else if (*pos == '"') {
			break;
		} else {
			out[i++] = *pos++;
		}
	}
	out[i] = '\0';
	return (int)i;
}

int json_escape(const char *src, char *dst, size_t dst_len)
{
	size_t j = 0;

	for (size_t i = 0; src[i] != '\0' && j + 2 < dst_len; i++) {
		unsigned char c = (unsigned char)src[i];

		if (c == '"') {
			dst[j++] = '\\';
			dst[j++] = '"';
		} else if (c == '\\') {
			dst[j++] = '\\';
			dst[j++] = '\\';
		} else if (c == '\n') {
			dst[j++] = '\\';
			dst[j++] = 'n';
		} else if (c == '\r') {
			dst[j++] = '\\';
			dst[j++] = 'r';
		} else if (c < 0x20) {
			dst[j++] = ' ';
		} else {
			dst[j++] = c;
		}
	}
	dst[j] = '\0';
	return (int)j;
}
```

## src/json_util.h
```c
/*
 * Copyright (c) 2026 Lingao Meng
 *
 * SPDX-License-Identifier: Apache-2.0
 *
 * zbot - JSON utility
 *
 * Minimal JSON string extraction with full escape sequence support:
 *   \n  \t  \"  \\  \uXXXX  (including UTF-16 surrogate pairs for emoji)
 */

#ifndef ZBOT_JSON_UTIL_H
#define ZBOT_JSON_UTIL_H

#include <stddef.h>

#ifdef __cplusplus
extern "C" {
#endif

/**
 * @brief Extract a JSON string value for @p key into @p out.
 *
 * Handles null values (writes empty string, returns 0) and all standard
 * JSON escape sequences including \uXXXX with UTF-16 surrogate pairs.
 *
 * @param json    JSON text to search.
 * @param key     Key name (without quotes).
 * @param out     Output buffer.
 * @param out_len Output buffer size.
 * @return Number of bytes written on success, -EINVAL on bad args,
 *         -ENOENT if key not found or value is not a string.
 */
int json_get_str(const char *json, const char *key, char *out, size_t out_len);

/**
 * @brief Escape a UTF-8 string for embedding in a JSON string value.
 *
 * Escapes \", \\, \n, \r and replaces other control characters with a space.
 * Does NOT add surrounding quotes.
 *
 * @param src     Input string.
 * @param dst     Output buffer.
 * @param dst_len Output buffer size.
 * @return Number of bytes written (excluding NUL terminator).
 */
int json_escape(const char *src, char *dst, size_t dst_len);

#ifdef __cplusplus
}
#endif

#endif /* ZBOT_JSON_UTIL_H */
```
